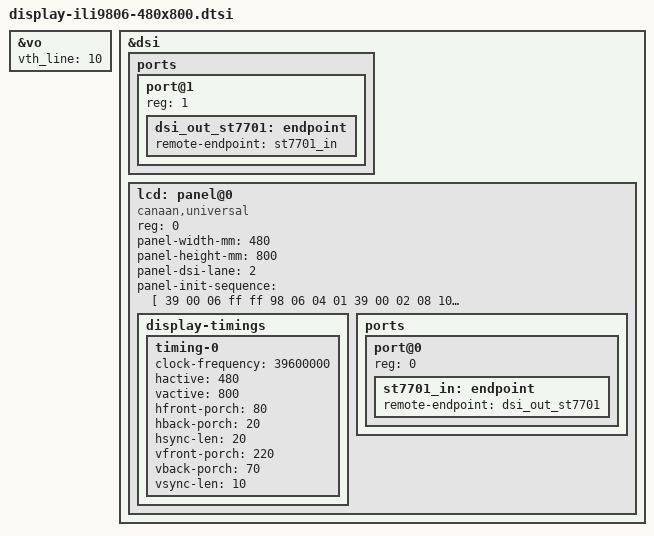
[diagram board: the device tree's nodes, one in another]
// SPDX-License-Identifier: GPL-2.0
&vo {
	vth_line = <10>;
};

&dsi {
	ports {
		port@1 {
			reg = <1>;
			dsi_out_st7701: endpoint {
				remote-endpoint = <&st7701_in>;
			};
		};
	};

	lcd: panel@0 {
		compatible = "canaan,universal";
		reg = <0>;

		panel-width-mm = <480>;
		panel-height-mm = <800>;
		panel-dsi-lane = <2>;

		panel-init-sequence = [
			39 00 06 ff ff 98 06 04 01
			39 00 02 08 10
			39 00 02 21 01
			39 00 02 30 02
			39 00 02 31 01
			39 00 02 40 16
			39 00 02 41 33
			39 00 02 42 00
			39 00 02 43 85
			39 00 02 44 8b
			39 00 02 45 1b
			39 00 02 50 78
			39 00 02 51 78
			39 00 02 52 00
			39 00 02 53 60
			39 00 02 60 07
			39 00 02 61 00
			39 00 02 62 07
			39 00 02 63 00
			39 00 02 a0 00
			39 00 02 a1 0b
			39 00 02 a2 12
			39 00 02 a3 0c
			39 00 02 a4 05
			39 00 02 a5 0c
			39 00 02 a6 07
			39 00 02 a7 16
			39 00 02 a8 06
			39 00 02 a9 0a
			39 00 02 aa 0f
			39 00 02 ab 06
			39 00 02 ac 0e
			39 00 02 ad 1a
			39 00 02 ae 12
			39 00 02 af 00
			39 00 02 c0 00
			39 00 02 c1 0b
			39 00 02 c2 12
			39 00 02 c3 0c
			39 00 02 c4 05
			39 00 02 c5 0c
			39 00 02 c6 07
			39 00 02 c7 16
			39 00 02 c8 06
			39 00 02 c9 0a
			39 00 02 ca 0f
			39 00 02 cb 06
			39 00 02 cc 0e
			39 00 02 cd 1a
			39 00 02 ce 12
			39 00 02 cf 00
			39 00 06 ff ff 98 06 04 06
			39 00 02 00 a0
			39 00 02 01 05
			39 00 02 02 00
			39 00 02 03 00
			39 00 02 04 01
			39 00 02 05 01
			39 00 02 06 88
			39 00 02 07 04
			39 00 02 08 01
			39 00 02 09 90
			39 00 02 0a 04
			39 00 02 0b 01
			39 00 02 0c 01
			39 00 02 0d 01
			39 00 02 0e 00
			39 00 02 0f 00
			39 00 02 10 55
			39 00 02 11 50
			39 00 02 12 01
			39 00 02 13 85
			39 00 02 14 85
			39 00 02 15 c0
			39 00 02 16 0b
			39 00 02 17 00
			39 00 02 18 00
			39 00 02 19 00
			39 00 02 1a 00
			39 00 02 1b 00
			39 00 02 1c 00
			39 00 02 1d 00
			39 00 02 20 01
			39 00 02 21 23
			39 00 02 22 45
			39 00 02 23 67
			39 00 02 24 01
			39 00 02 25 23
			39 00 02 26 45
			39 00 02 27 67
			39 00 02 30 02
			39 00 02 31 22
			39 00 02 32 11
			39 00 02 33 aa
			39 00 02 34 bb
			39 00 02 35 66
			39 00 02 36 00
			39 00 02 37 22
			39 00 02 38 22
			39 00 02 39 22
			39 00 02 3a 22
			39 00 02 3b 22
			39 00 02 3c 22
			39 00 02 3d 20
			39 00 02 3e 22
			39 00 02 3f 22
			39 00 02 40 22
			39 00 02 53 1a
			39 00 06 ff ff 98 06 04 07
			39 00 02 17 12
			39 00 01 21
			39 00 02 02 77
			39 00 06 ff ff 98 06 04 00
			39 00 02 35 00
			39 00 01 11
			39 ff 01 29
		];

		display-timings {
				timing-0 {
				clock-frequency = <39600000>;
				hactive = <480>;
				vactive = <800>;
				hfront-porch = <80>;
				hback-porch = <20>;
				hsync-len = <20>;
				vfront-porch = <220>;
				vback-porch = <70>;
				vsync-len = <10>;
			};
		};

		ports {
			#address-cells = <1>;
			#size-cells = <0>;

			port@0 {
				reg = <0>;
				st7701_in: endpoint {
					remote-endpoint = <&dsi_out_st7701>;
				};
			};
		};
	};
};
